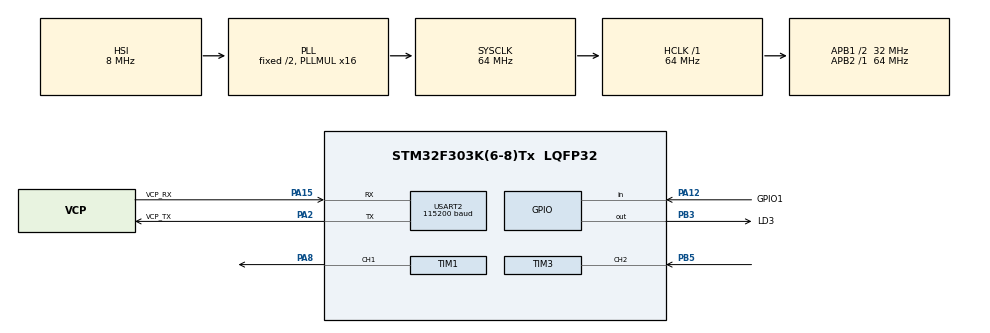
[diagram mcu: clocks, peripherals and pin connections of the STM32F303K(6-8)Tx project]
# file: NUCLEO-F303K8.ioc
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Mcu.Family=STM32F3
Mcu.Name=STM32F303K(6-8)Tx
Mcu.Package=LQFP32
NVIC.PriorityGroup=NVIC_PRIORITYGROUP_4
PA13.GPIO_Label=SWDIO
PA13.Mode=Serial_Wire
PA13.Signal=SYS_JTMS-SWDIO
PA14.GPIO_Label=SWCLK
PA14.Mode=Serial_Wire
PA14.Signal=SYS_JTCK-SWCLK
PA15.GPIO_Label=VCP_RX
PA15.Mode=Asynchronous
PA15.Signal=USART2_RX
PA2.GPIO_Label=VCP_TX
PA2.Mode=Asynchronous
PA2.Signal=USART2_TX
ProjectManager.HeapSize=0x200
ProjectManager.StackSize=0x400
ProjectManager.TargetToolchain=STM32CubeIDE
RCC.AHBFreq_Value=64000000
RCC.APB1CLKDivider=RCC_HCLK_DIV2
RCC.APB1Freq_Value=32000000
RCC.APB1TimFreq_Value=64000000
RCC.APB2Freq_Value=64000000
RCC.APB2TimFreq_Value=64000000
RCC.CortexFreq_Value=64000000
RCC.HCLKFreq_Value=64000000
RCC.HSE_VALUE=8000000
RCC.HSI_VALUE=8000000
RCC.PLLMUL=RCC_PLL_MUL16
RCC.PLLSourceVirtual=RCC_PLLSOURCE_HSI
RCC.SYSCLKFreq_VALUE=64000000
RCC.SYSCLKSourceVirtual=RCC_SYSCLKSOURCE_PLLCLK
USART2.VirtualMode-Asynchronous=VM_ASYNC
board=NUCLEO-F303K8
PA8.Signal=S_TIM1_CH1
USART2.BaudRate=115200
Dma.Request0=USART2_RX
Dma.USART2_RX.0.Instance=DMA1_Channel6
Dma.USART2_RX.0.Direction=DMA_PERIPH_TO_MEMORY
Dma.USART2_RX.0.PeriphInc=DMA_PINC_DISABLE
Dma.USART2_RX.0.MemInc=DMA_MINC_ENABLE
Dma.USART2_RX.0.PeriphDataAlignment=DMA_PDATAALIGN_BYTE
Dma.USART2_RX.0.MemDataAlignment=DMA_MDATAALIGN_BYTE
Dma.USART2_RX.0.Mode=DMA_CIRCULAR
Dma.USART2_RX.0.Priority=DMA_PRIORITY_LOW
NVIC.DMA1_Channel6_IRQn=true\:0\:0\:false\:false\:true\:true\:true\:true
NVIC.USART2_IRQn=true\:0\:0\:false\:false\:true\:true\:true\:true
NVIC.TIM1_UP_TIM16_IRQn=true\:0\:0\:false\:false\:true\:true\:true\:true
NVIC.TIM1_CC_IRQn=true\:0\:0\:false\:false\:true\:true\:true\:true
SH.S_TIM1_CH1.0=TIM1_CH1,PWM Generation1 CH1
SH.S_TIM3_CH2.0=TIM3_CH2,TriggerSource_TI2FP2
TIM1.AutoReloadPreload=TIM_AUTORELOAD_PRELOAD_ENABLE
TIM1.Channel-PWM\ Generation1\ CH1=TIM_CHANNEL_1
TIM1.Prescaler=63
TIM1.Period=999
TIM1.Pulse-PWM\ Generation1\ CH1=500
TIM1.OffStateIDLEMode=TIM_OSSI_ENABLE
TIM1.OCIdleState_1=TIM_OCIDLESTATE_SET
TIM3.SlaveMode=TIM_SLAVEMODE_EXTERNAL1
TIM3.InputTrigger=TIM_TS_TI2FP2
TIM3.Period=65535
VP_TIM1_VS_ClockSourceINT.Mode=Internal
VP_TIM3_VS_ControllerModeClock.Mode=Clock Mode
PB5.Signal=S_TIM3_CH2
PA12.Signal=GPIO_Input
PA12.GPIO_Label=GPIO1
PB3.Signal=GPIO_Output
PB3.GPIO_Label=LD3
NVIC.TIM3_IRQn=true\:0\:0\:false\:false\:true\:true\:true\:true
RCC.HSICalibrationValue=RCC_HSICALIBRATION_DEFAULT

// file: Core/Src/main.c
/* USER CODE BEGIN Header */
/**
  ******************************************************************************
  * @file           : main.c
  * @brief          : Main program body
  ******************************************************************************
  * @attention
  *
  * Copyright (c) 2026 STMicroelectronics.
  * All rights reserved.
  *
  * This software is licensed under terms that can be found in the LICENSE file
  * in the root directory of this software component.
  * If no LICENSE file comes with this software, it is provided AS-IS.
  *
  ******************************************************************************
  */
/* USER CODE END Header */
#include "main.h"
#include "usart.h"
#include "gpio.h"

/* USER CODE BEGIN Includes */
#include "app.h"
#include "tim.h"
#include "dma.h"

/* USER CODE END Includes */

void SystemClock_Config(void);

int main(void)
{

  /* MCU Configuration--------------------------------------------------------*/

  /* Reset of all peripherals, Initializes the Flash interface and the Systick. */
  HAL_Init();

  /* Configure the system clock */
  SystemClock_Config();

  /* Initialize all configured peripherals */
  MX_GPIO_Init();
  MX_DMA_Init();
  MX_TIM1_Init();
  MX_TIM3_Init();
  MX_USART2_UART_Init();
  /* USER CODE BEGIN 2 */
  app_main();

  /* USER CODE END 2 */

  /* Infinite loop */
  while (1)
  {

  }
}

void SystemClock_Config(void)
{
  RCC_OscInitTypeDef RCC_OscInitStruct = {0};
  RCC_ClkInitTypeDef RCC_ClkInitStruct = {0};

  /** Initializes the RCC Oscillators according to the specified parameters
  * in the RCC_OscInitTypeDef structure.
  */
  RCC_OscInitStruct.OscillatorType = RCC_OSCILLATORTYPE_HSI;
  RCC_OscInitStruct.HSEState = RCC_HSE_OFF;
  RCC_OscInitStruct.HSICalibrationValue = RCC_HSICALIBRATION_DEFAULT;
  RCC_OscInitStruct.HSIState = RCC_HSI_ON;
  RCC_OscInitStruct.PLL.PLLState = RCC_PLL_ON;
  RCC_OscInitStruct.PLL.PLLSource = RCC_PLLSOURCE_HSI;
  RCC_OscInitStruct.PLL.PLLMUL = RCC_PLL_MUL16;
  if (HAL_RCC_OscConfig(&RCC_OscInitStruct) != HAL_OK)
  {
    Error_Handler();
  }

  /** Initializes the CPU, AHB and APB buses clocks
  */
  RCC_ClkInitStruct.ClockType = RCC_CLOCKTYPE_HCLK|RCC_CLOCKTYPE_SYSCLK
                              |RCC_CLOCKTYPE_PCLK1|RCC_CLOCKTYPE_PCLK2;
  RCC_ClkInitStruct.SYSCLKSource = RCC_SYSCLKSOURCE_PLLCLK;
  RCC_ClkInitStruct.AHBCLKDivider = RCC_SYSCLK_DIV1;
  RCC_ClkInitStruct.APB1CLKDivider = RCC_HCLK_DIV2;
  RCC_ClkInitStruct.APB2CLKDivider = RCC_HCLK_DIV1;

  if (HAL_RCC_ClockConfig(&RCC_ClkInitStruct, FLASH_LATENCY_2) != HAL_OK)
  {
    Error_Handler();
  }
}

void Error_Handler(void)
{
  __disable_irq();
  while (1)
  {
  }
}
